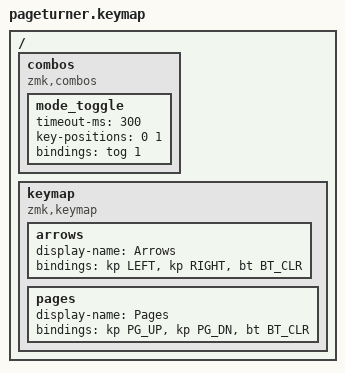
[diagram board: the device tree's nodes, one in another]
#include <behaviors.dtsi>
#include <dt-bindings/zmk/keys.h>
#include <dt-bindings/zmk/bt.h>

/ {
    combos {
        compatible = "zmk,combos";

        mode_toggle {
            timeout-ms = <300>;
            key-positions = <0 1>;
            bindings = <&tog 1>;
        };
    };

    keymap {
        compatible = "zmk,keymap";

        arrows {
            display-name = "Arrows";
            bindings = <
                &kp LEFT
                &kp RIGHT
                &bt BT_CLR
            >;
        };

        pages {
            display-name = "Pages";
            bindings = <
                &kp PG_UP
                &kp PG_DN
                &bt BT_CLR
            >;
        };
    };
};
